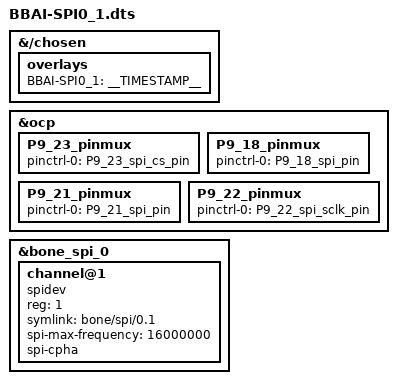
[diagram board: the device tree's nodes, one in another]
/*
 * Copyright (C) 2020 Deepak Khatri <deepaklorkhatri7@gmail.com>
 * https://lorforlinux.github.io/GSoC2020_BeagleBoard.org/
 *
 * See Cape Interface Spec page for more info on Bone Buses
 * https://elinux.org/Beagleboard:BeagleBone_cape_interface_spec
 *
 * BBAI Virtual cape for /dev/bone/spi/0.1
 *
 * This program is free software; you can redistribute it and/or modify
 * it under the terms of the GNU General Public License version 2 as
 * published by the Free Software Foundation.
 */

/dts-v1/;
/plugin/;

/*
* Helper to show loaded overlays under: /proc/device-tree/chosen/overlays/
*/
&{/chosen} {
    overlays {
        BBAI-SPI0_1 = __TIMESTAMP__;
    };
};

/*
 * Update the default pinmux of the pins.
 * See these files for the phandles (&P9_* & &P8_*)
 * BeagleBoard-DeviceTrees/v4.19.x-ti-overlays/src/arm/am335x-bone-common-univ.dtsi
 * BeagleBoard-DeviceTrees/v4.19.x-ti-overlays/src/arm/am572x-bone-common-univ.dtsi
 */
&ocp {
    P9_23_pinmux { pinctrl-0 = <&P9_23_spi_cs_pin>; }; /* CS */
    P9_18_pinmux { pinctrl-0 = <&P9_18_spi_pin>; }; /* MOSI */
    P9_21_pinmux { pinctrl-0 = <&P9_21_spi_pin>; }; /* MISO */
    P9_22_pinmux { pinctrl-0 = <&P9_22_spi_sclk_pin>; }; /* CLK */
};

/*
 * See these files for the phandles (&bone_*) and other bone bus nodes
 * BeagleBoard-DeviceTrees/v4.19.x-ti-overlays/src/arm/bbai-bone-buses.dtsi
 * BeagleBoard-DeviceTrees/v4.19.x-ti-overlays/src/arm/bbb-bone-buses.dtsi
 */
&bone_spi_0 {
	status = "okay";
    #address-cells = <1>;
    #size-cells = <0>;

	channel@1 {
		reg = <1>;
		compatible = "spidev";
		symlink = "bone/spi/0.1";
		spi-max-frequency = <16000000>;
        spi-cpha;
	};
};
